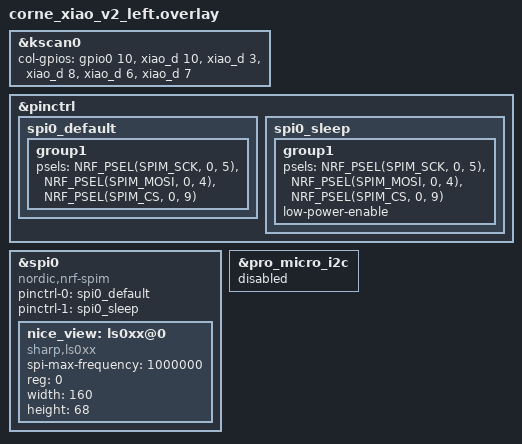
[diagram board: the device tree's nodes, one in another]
#include "corne_xiao_v2.dtsi"

&kscan0 {
    col-gpios
        = <&gpio0 10 GPIO_ACTIVE_HIGH>
        , <&xiao_d 10 GPIO_ACTIVE_HIGH>
        , <&xiao_d 3 GPIO_ACTIVE_HIGH>
        , <&xiao_d 8 GPIO_ACTIVE_HIGH>
        , <&xiao_d 6 GPIO_ACTIVE_HIGH>
        , <&xiao_d 7 GPIO_ACTIVE_HIGH>
        ;
};

&pinctrl {
	spi0_default: spi0_default {
		group1 {
			psels = <NRF_PSEL(SPIM_SCK, 0, 5)>
			 	    <NRF_PSEL(SPIM_MOSI, 0, 4)>
                    <NRF_PSEL(SPIM_CS, 0, 9)>;
		};
	};
	spi0_sleep: spi0_sleep {
		group1 {
			psels = <NRF_PSEL(SPIM_SCK, 0, 5)>
			    	<NRF_PSEL(SPIM_MOSI, 0, 4)>
                    <NRF_PSEL(SPIM_CS, 0, 9)>;
			low-power-enable;
		};
	};	
};


display_spi: &spi0 {
	compatible = "nordic,nrf-spim";
	pinctrl-0 = <&spi0_default>;
	pinctrl-1 = <&spi0_sleep>;
	pinctrl-names = "default", "sleep";
};

&display_spi {
    status = "okay";
    nice_view: ls0xx@0 {
        compatible = "sharp,ls0xx";
        spi-max-frequency = <1000000>;
        reg = <0>;
        width = <160>;
        height = <68>;
    };
};

&pro_micro_i2c {
    status = "disabled";
};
